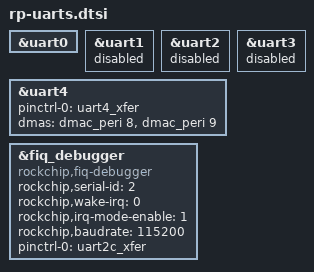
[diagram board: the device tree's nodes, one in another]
//used to bluetooth
&uart0 {
    status = "okay";
    //dma-names = "tx", "rx";
    //dmas = <&dmac_peri 0>, <&dmac_peri 1>;
};

//conflicts to ethernet
&uart1 {
    status = "disabled";
    //dma-names = "tx", "rx";
    //dmas = <&dmac_peri 2>, <&dmac_peri 3>;
};

//conflicts to debugger
&uart2 {
    status = "disabled";
    //dma-names = "tx", "rx";
    //dmas = <&dmac_peri 4>, <&dmac_peri 5>;
};

//conflicts to ethernet
&uart3 {
    status = "disabled";
    //dma-names = "tx", "rx";
    //dmas = <&dmac_peri 6>, <&dmac_peri 7>;
};

&uart4 {
    status = "okay";
    pinctrl-names = "default";
    pinctrl-0 = <&uart4_xfer>;
    dma-names = "tx", "rx";
    dmas = <&dmac_peri 8>, <&dmac_peri 9>;
};

&fiq_debugger {
    rockchip,serial-id = <2>; //uart2
    rockchip,wake-irq = <0>;
    rockchip,irq-mode-enable = <1>;
    compatible = "rockchip,fiq-debugger";
    rockchip,baudrate = <115200>;
    pinctrl-names = "default";
    pinctrl-0 = <&uart2c_xfer>;
};
